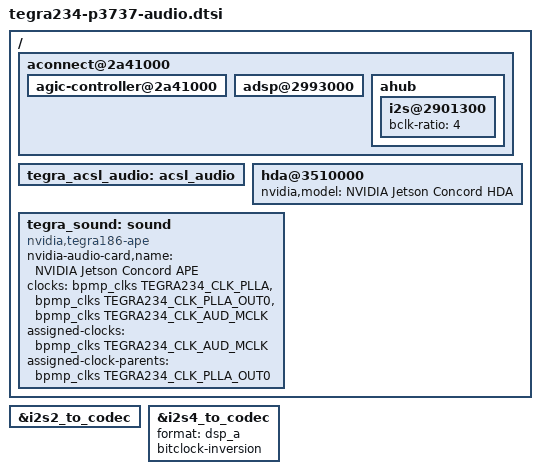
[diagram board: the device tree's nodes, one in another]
/*
 * T234 p3737 audio DTSI file.
 *
 * Copyright (c) 2021, NVIDIA CORPORATION.  All rights reserved.
 *
 * This program is free software; you can redistribute it and/or modify
 * it under the terms of the GNU General Public License as published by
 * the Free Software Foundation; version 2 of the License.
 *
 * This program is distributed in the hope that it will be useful, but WITHOUT
 * ANY WARRANTY; without even the implied warranty of MERCHANTABILITY or
 * FITNESS FOR A PARTICULAR PURPOSE.  See the GNU General Public License for
 * more details.
 */

#include <audio/tegra-platforms-audio-dai-links.dtsi>
#include <audio/tegra186-audio-dai-links.dtsi>
#include <dt-bindings/gpio/tegra234-gpio.h>
#include <dt-bindings/audio/tegra234-audio.h>
#include <audio/tegra-platforms-audio-dmic3-5-switch.dtsi>

/ {
	aconnect@2a41000 {
		status = "okay";

		agic-controller@2a41000 {
			status = "okay";
		};

		adsp@2993000 {
			status = "okay";
		};

		ahub {
			/* I2S4 in Short frame sync for BT SCO */
			i2s@2901300 {
				bclk-ratio = <4>;
			};
		};
	};

	tegra_acsl_audio: acsl_audio {
		status = "okay";
	};

	hda@3510000 {
		nvidia,model = "NVIDIA Jetson Concord HDA";
		status = "okay";
	};

	tegra_sound: sound {
		status = "okay";
		compatible = "nvidia,tegra186-ape";
		nvidia-audio-card,name = "NVIDIA Jetson Concord APE";
		clocks = <&bpmp_clks TEGRA234_CLK_PLLA>,
			 <&bpmp_clks TEGRA234_CLK_PLLA_OUT0>,
			 <&bpmp_clks TEGRA234_CLK_AUD_MCLK>;
		clock-names = "pll_a", "pll_a_out0", "extern1";
		assigned-clocks = <&bpmp_clks TEGRA234_CLK_AUD_MCLK>;
		assigned-clock-parents = <&bpmp_clks TEGRA234_CLK_PLLA_OUT0>;
	};
};

/*
 * Default config for all I2S dai links are
 * format = "i2s", bitclock-slave, frame-slave,
 * bitclock-noninversion, frame-noninversion,
 * Any change from default needs override on
 * platform specific files.
 */

hdr40_snd_link_i2s: &i2s2_to_codec { };

/* Override with BT SCO entries */
&i2s4_to_codec {
	format = "dsp_a";
	bitclock-inversion;
};
